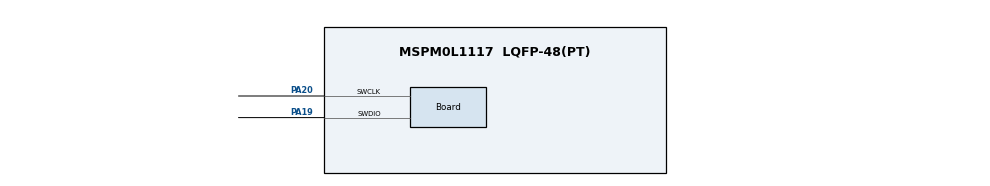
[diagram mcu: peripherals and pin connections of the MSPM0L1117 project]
//@cliArgs --device "MSPM0L111X" --package "LQFP-48(PT)" --part "Default"
//@v2CliArgs --device "MSPM0L1117" --package "LQFP-48(PT)"
// @cliArgs --board /ti/boards/LP_MSPM0L1117 --rtos nortos

/**
 * Import the modules used in this configuration.
 */
const ADC12  = scripting.addModule("/ti/driverlib/ADC12", {}, false);
const ADC121 = ADC12.addInstance();
const Board  = scripting.addModule("/ti/driverlib/Board");
const SYSCTL = scripting.addModule("/ti/driverlib/SYSCTL");
const UART   = scripting.addModule("/ti/driverlib/UART", {}, false);
const UART1  = UART.addInstance();

/**
 * Write custom configuration values to the imported modules.
 */
ADC121.$name                      = "ADC12_0";
ADC121.enabledInterrupts          = ["DL_ADC12_INTERRUPT_MEM0_RESULT_LOADED"];
ADC121.sampleTime0                = "125 us";
ADC121.sampClkSrc                 = "DL_ADC12_CLOCK_ULPCLK";
ADC121.sampClkDiv                 = "DL_ADC12_CLOCK_DIVIDE_8";
ADC121.adcMem0chansel             = "DL_ADC12_INPUT_CHAN_2";
ADC121.peripheral.$assign         = "ADC0";
ADC121.peripheral.adcPin2.$assign = "PA25";

Board.peripheral.$assign          = "DEBUGSS";
Board.peripheral.swclkPin.$assign = "PA20";
Board.peripheral.swdioPin.$assign = "PA19";

SYSCTL.peripheral.$assign = "SYSCTL";

UART1.$name              = "UART_0";
UART1.enableFIFO         = true;
UART1.direction          = "TX";
UART1.rxFifoThreshold    = "DL_UART_RX_FIFO_LEVEL_ONE_ENTRY";
UART1.peripheral.$assign = "UART0";

const ProjectConfig              = scripting.addModule("/ti/project_config/ProjectConfig", {}, false);
ProjectConfig.migrationCondition = true;
